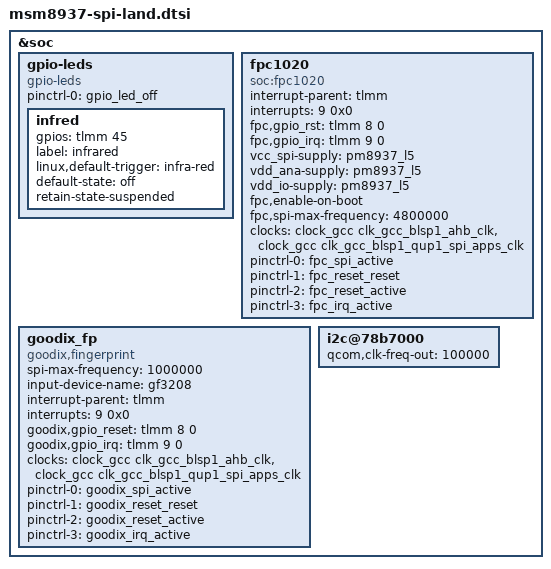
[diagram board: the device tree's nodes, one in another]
&soc {
	gpio-leds {
		compatible = "gpio-leds";
		status = "okay";
		pinctrl-names = "default";
		pinctrl-0 = <&gpio_led_off>;

		infred {
			gpios = <&tlmm 45 0>;
			label = "infrared";
			linux,default-trigger = "infra-red";
			default-state = "off";
			retain-state-suspended;
		};

	};

	fpc1020 {
		compatible = "soc:fpc1020";

		interrupt-parent = <&tlmm>;
		interrupts = <9 0x0>;

		fpc,gpio_rst    = <&tlmm 8 0>;
		fpc,gpio_irq    = <&tlmm 9 0>;

		vcc_spi-supply  = <&pm8937_l5>;
		vdd_ana-supply  = <&pm8937_l5>;
		vdd_io-supply   = <&pm8937_l5>;

		fpc,enable-on-boot;
		/delete-property/ fpc,enable-wakeup;

		fpc,spi-max-frequency = <4800000>;

		clock-names = "iface_clk", "core_clk";
		clocks = <&clock_gcc clk_gcc_blsp1_ahb_clk>,
				<&clock_gcc clk_gcc_blsp1_qup1_spi_apps_clk>;

		pinctrl-names = "fpc1020_spi_active",
				"fpc1020_reset_reset",
				"fpc1020_reset_active",
				"fpc1020_irq_active";

		pinctrl-0 = <&fpc_spi_active>;
		pinctrl-1 = <&fpc_reset_reset>;
		pinctrl-2 = <&fpc_reset_active>;
		pinctrl-3 = <&fpc_irq_active>;
	};

	goodix_fp {
		compatible = "goodix,fingerprint";
		spi-max-frequency = <1000000>;
		input-device-name = "gf3208";
		interrupt-parent = <&tlmm>;
		interrupts = <9 0x0>;

		goodix,gpio_reset    = <&tlmm 8 0>;
		goodix,gpio_irq      = <&tlmm 9 0>;

		clock-names = "iface_clk", "core_clk";
		clocks = <&clock_gcc clk_gcc_blsp1_ahb_clk>,
				<&clock_gcc clk_gcc_blsp1_qup1_spi_apps_clk>;

		pinctrl-names = "goodixfp_spi_active",
				"goodixfp_reset_reset",
				"goodixfp_reset_active",
				"goodixfp_irq_active";

		pinctrl-0 = <&goodix_spi_active>;
		pinctrl-1 = <&goodix_reset_reset>;
		pinctrl-2 = <&goodix_reset_active>;
		pinctrl-3 = <&goodix_irq_active>;
	};

	i2c@78b7000 {
		qcom,clk-freq-out = <100000>;
		status = "okay";
	};
};
